# nrf7120E_enga_application register map
Vendor: Nordic Semiconductor; Series: nrf71; File version: 1
CPU: CM33 r0p4, little endian, MPU, FPU, 3 interrupt priority bits, 270 interrupts, 4 SAU regions
Registers are 32-bit, read-write, reset 0x0 unless marked. A register's access mark holds for its fields unless they carry their own. Offsets are from the block's base; [hi:lo] are bit positions; lines under a group give offsets from that group; {n}, {i} and the like mark numbered series; 'fields as' and 'values as' point back to an identical list.

## GLOBAL_MRAMC_S — MRAM controller
Base 0x5004E000
0x100 EVENTS_READY — Current operation is completed
  [0] EVENTS_READY
    0=NotGenerated (Event not generated); 1=Generated (Event generated)
0x104 EVENTS_READYNEXT — Ready to accept a new write operation
  [0] EVENTS_READYNEXT
    values as EVENTS_READY.EVENTS_READY
0x108 EVENTS_ECCERROR — ECC error detected but not corrected.
  [0] EVENTS_ECCERROR
    values as EVENTS_READY.EVENTS_READY
0x10C EVENTS_ECCERRORCORR — ECC error detected and corrected.
  [0] EVENTS_ECCERRORCORR
    values as EVENTS_READY.EVENTS_READY
0x110 EVENTS_TRIMCONFIGREQ — MRAM trim configuration request. The MRAMC is ready for the MRAM trim configuration.
  [0] EVENTS_TRIMCONFIGREQ
    values as EVENTS_READY.EVENTS_READY
0x114 EVENTS_ACCESSERR — MRAM access error.
  [0] EVENTS_ACCESSERR
    values as EVENTS_READY.EVENTS_READY
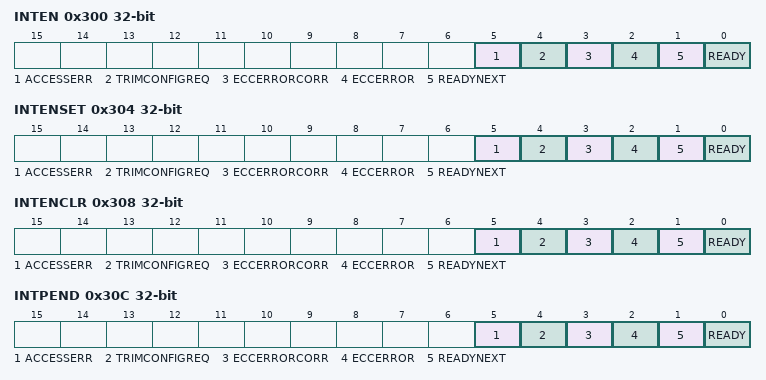
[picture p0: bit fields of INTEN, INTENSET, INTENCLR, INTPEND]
0x300 INTEN — Enable or disable interrupt
  [all] fields
    0=Disabled; 1=Enabled
  [5] ACCESSERR — Enable or disable interrupt for event ACCESSERR
  [4] TRIMCONFIGREQ — Enable or disable interrupt for event TRIMCONFIGREQ
  [3] ECCERRORCORR — Enable or disable interrupt for event ECCERRORCORR
  [2] ECCERROR — Enable or disable interrupt for event ECCERROR
  [1] READYNEXT — Enable or disable interrupt for event READYNEXT
  [0] READY — Enable or disable interrupt for event READY
0x304 INTENSET — Enable interrupt
  [all] fields
    on read: 0=Disabled (Read: Disabled); 1=Enabled (Read: Enabled) | on write: 1=Set (Enable)
  [5] ACCESSERR write-1-sets — Write '1' to enable interrupt for event ACCESSERR
  [4] TRIMCONFIGREQ write-1-sets — Write '1' to enable interrupt for event TRIMCONFIGREQ
  [3] ECCERRORCORR write-1-sets — Write '1' to enable interrupt for event ECCERRORCORR
  [2] ECCERROR write-1-sets — Write '1' to enable interrupt for event ECCERROR
  [1] READYNEXT write-1-sets — Write '1' to enable interrupt for event READYNEXT
  [0] READY write-1-sets — Write '1' to enable interrupt for event READY
0x308 INTENCLR — Disable interrupt
  [all] fields
    on read: 0=Disabled (Read: Disabled); 1=Enabled (Read: Enabled) | on write: 1=Clear (Disable)
  [5] ACCESSERR write-1-clears — Write '1' to disable interrupt for event ACCESSERR
  [4] TRIMCONFIGREQ write-1-clears — Write '1' to disable interrupt for event TRIMCONFIGREQ
  [3] ECCERRORCORR write-1-clears — Write '1' to disable interrupt for event ECCERRORCORR
  [2] ECCERROR write-1-clears — Write '1' to disable interrupt for event ECCERROR
  [1] READYNEXT write-1-clears — Write '1' to disable interrupt for event READYNEXT
  [0] READY write-1-clears — Write '1' to disable interrupt for event READY
0x30C INTPEND ro — Pending interrupts
  [all] fields
    on read: 0=NotPending (Read: Not pending); 1=Pending (Read: Pending)
  [5] ACCESSERR — Read pending status of interrupt for event ACCESSERR
  [4] TRIMCONFIGREQ — Read pending status of interrupt for event TRIMCONFIGREQ
  [3] ECCERRORCORR — Read pending status of interrupt for event ECCERRORCORR
  [2] ECCERROR — Read pending status of interrupt for event ECCERROR
  [1] READYNEXT — Read pending status of interrupt for event READYNEXT
  [0] READY — Read pending status of interrupt for event READY
0x400 READY ro — MRAMC current operation status.
  [0] READY — MRAMC is ready or busy
    0=Busy (MRAMC is busy); 1=Ready (Current operation is completed and MRAMC is ready)
0x404 READYNEXT ro — Ready next flag.
  [0] READYNEXT — MRAMC can accept a new write operation
    0=Busy (MRAMC cannot accept any write operation now); 1=Ready (MRAMC is ready to accept a new write operation)
0x410 ECC group — Unspecified
  0x00 ERROR — ECC Error status.
    [0] ECCERROR — ECC error detected for a read which could not be corrected. Write 0 to clear.
      0=NoEccError (ECC error not detected); 1=ECC error detected
  0x04 ERRORCORR — ECC error detected and corrected.
    [0] ERRORCORR — ECC error detected and corrected for a read. Write 0 to clear.
      0=NoEccError (ECC error not detected); 1=ErrorCorr (ECC error detected and corrected)
  0x08 ERRORADDR ro reset 0xFFFFFFFF — Address of the first ECC error that could not be corrected.
    [31:0] ERRORADDR — Address
  0x0C CORRADDR ro reset 0xFFFFFFFF — Address of the first ECC error that was corrected.
    [31:0] CORRADDR — Address
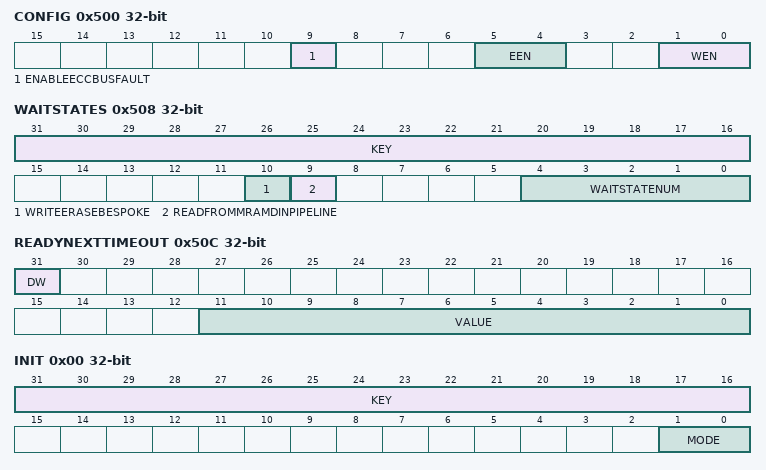
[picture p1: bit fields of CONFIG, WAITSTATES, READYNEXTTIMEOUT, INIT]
0x500 CONFIG — Configuration register
  [9] ENABLEECCBUSFAULT — Enable or disable bus fault on ECC failure during read.
    0=Enable bus fault on ECC failure during MRAM read; 1=Disable bus fault on ECC failure during MRAM read
  [5:4] EEN — Erase enable.
    0=DisableErase (Erase is disabled but read is allowed); 1=EnablePageErase (Erase page and read are allowed); 2=EnableWordErase (Erase word and read are allowed)
  [1:0] WEN — Write enable.
    0=DisableWrite (Write is disabled); 1=EnableNormalWrite (Normal write is enabled); 2=EnableDirectWrite (Direct write is enabled)
0x504 AUTOREADMODE — Automatically disables the write and erases on timeout and enters into read mode.
  [11:0] VALUE — Timeout value to disable write and erase.
0x508 WAITSTATES — Waitstates for MRAM read access
  [31:16] KEY — Key to enable the writing to this register.
    0=Disable the writing to this register; 0xA66D=Enable the writing to this register
  [10] WRITEERASEBESPOKE — Select the operational mode for the bespoke request.
    0=ModeEntryExit (Send the bespoke signal when entering either write or erase mode, and release the request when exiting those modes.); 1=ModeEnable (Send the bespoke request when a write or an erase is enabled in.)
  [9] READFROMMRAMDINPIPELINE — Register to enable or disable reading data pending to be committed to MRAM from the data input pipeline if the data at the requested read address is already present in the MRAM data input pipeline. Only applicable for direct write mode.
    0=Disable reading uncommitted data from MRAM data input pipeline; 1=Enable reading uncommitted data from MRAM data input pipeline
  [4:0] WAITSTATENUM — Register to read the current number of waitstate for the MRAM access and set a new value
0x50C READYNEXTTIMEOUT — Preload timeout value for waiting for a next write
  [31] DW — Triggers a write to MRAMC macro on the ready next timeout in direct write mode (CONFIG.WEN = 2) and some data written into the internal write buffer.
    0=Disable (No write trigger); 1=Enable (Write trigger)
  [11:0] VALUE — Preload value
0x510 LOWAVGCURR group — Unspecified
  0x00 READ — Preload timeout value for low average current in case of read
    [11:0] VALUE — Preload value
  0x04 WRITE — Preload timeout value for low average current in case of write
    [11:0] VALUE — Preload value
  0x08 ERASE — Preload timeout value for low average current in case of erase
    [11:0] VALUE — Preload value
0x520 POWER group — Unspecified
  0x00 INIT — Initiates power up or down sequence.
    [31:16] KEY — Key to enable the writing to this register.
      values as WAITSTATES.KEY
    [1:0] MODE — Power mode.
      0=NoOperation (No change in power mode); 1=PowerUp (Triggers power up sequence. Ignored if MRAM is already in Active mode or Standby mode.); 2=PowerDown (Initiates power down sequence. Ignored if MRAM is already in MRAM_OFF mode.); 3=PowerDownTrimRet (Initiates power down sequence with trim retained. Ignored if MRAM is already in MRAM_OFF_TRIM_RETAIN mode.)
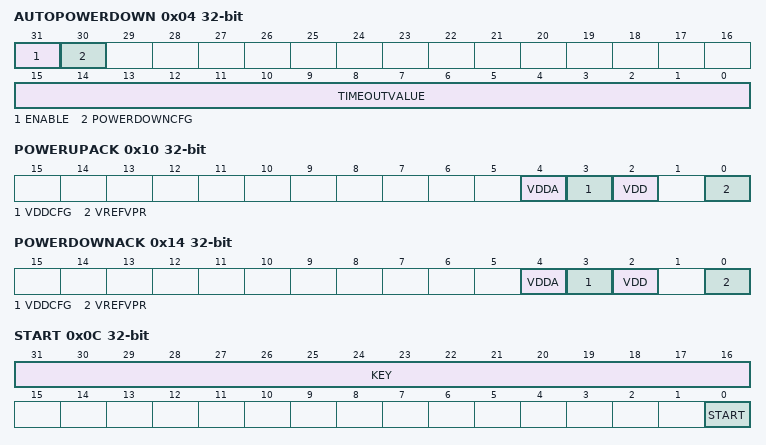
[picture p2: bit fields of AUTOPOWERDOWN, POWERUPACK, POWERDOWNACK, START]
  0x04 AUTOPOWERDOWN — Configures the automatic power down feature using the inactive time period of MRAM.
    [31] ENABLE — Enable the automatic power down feature.
      0=Disable the automatic power down feature; 1=Enable the automatic power down feature
    [30] POWERDOWNCFG — Power down mode when the timeout happens.
      0=MramOffTrimRetain (Power mode is MRAM_OFF_TRIM_RETAIN); 1=MramOff (Power mode is MRAM_OFF)
    [15:0] TIMEOUTVALUE — Timeout value for the power down.
  0x0C STATUS ro — Status of the power up/down sequence.
    [3:0] STATE — The current power up/down state.
      0=Off (MRAM is OFF); 1=PowerUpSeq (MRAM power up sequence is active); 2=TrimConfigSeq (Request for the MRAM trim configuration.); 3=TrimConfigWait (Waiting for the MRAM trim configuration to complete.); 4=TrimConfigDone (The MRAM trim configuration to completed (This is momentary state).); 5=Standby (MRAM is in standby mode.); 6=Active (MRAM is in active mode (or in standby mode)); 7=PowerDownSeq (MRAM power down sequence is active); 8=OffTrimRetain (MRAM is OFF with trim configuration in retain)
  0x10 POWERUPACK ro — Status of the power control signals acknowledgement during power up sequence.
    [all] fields
      0=Busy; 1=Ready
    [4] VDDA — Waiting for VDDA up ACK or not
    [3] VDDCFG — Waiting for VDD_CFG up ACK or not
    [2] VDD — Waiting for VDD up ACK or not
    [0] VREFVPR — Waiting for VREF and VPR up ACK or not
  0x14 POWERDOWNACK ro — Status of the power control signals acknowledgement during power down sequence.
    [all] fields
      0=Busy; 1=Ready
    [4] VDDA — Waiting for VDDA down ACK or not
    [3] VDDCFG — Waiting for VDD_CFG down ACK or not
    [2] VDD — Waiting for VDD down ACK or not
    [0] VREFVPR — Waiting for VREF and VPR down ACK or not
0x540 TRIM group — Unspecified
  0x00 DATAIN reset 0xFFFFFFFF — Data to be written to the MRAM trim configuration.
    [31:0] DATAIN — Data
  0x04 DATAOUT ro — Data read from the MRAM trim configuration.
    [31:0] DATAOUT — Data
  0x08 COUNT reset 0x20 — Number of bits in the current data to be written to and read from the trim configuration.
    [5:0] COUNT — Number of bits to be written.
  0x0C START — Start shifting data for trim configuration.
    [31:16] KEY — Key to enable the writing to this register.
      values as WAITSTATES.KEY
    [0] START — Start trim configuration
      0=NoOperation; 1=Start trim config
  0x10 READY ro reset 0x1 — Status of shifting the MRAM trim configuration data.
    [0] READY — Shifting the MRAM trim configuration data is in progress or not.
      0=Busy (Shifting the MRAM trim configuration data is in progress.); 1=Ready for shifting the next MRAM trim configuration data
  0x14 DONE — This register is used to indicate to the MRAMC that the whole MRAM trim configuration data write is completed.
    [31:0] TRIMCOMPLETED — Trim configuration is completed.
      on read: 0=TrimUnknown (Read: Trim configuration is unknown); 1=TrimCompleted (Read: Trim configuration data write is completed.) | on write: 0xA66DA66D=TrimComplete (Write: Trim configuration data write is complete.); 0=NoOperation (Write ignored for all other values than 0xA66DA66D.)
0x560 ERASE group — Unspecified
  0x00 ERASEWORD — Register for erasing a word in the MRAM main block.
    [31:0] ERASEWORD — Address of the word that needs to be erased.
  0x04 SIZE — Size for erasing an area in the MRAM main block
    [18:0] SIZE — Number of MRAM words to be erased using ERASE.ERASEAREA.
  0x08 ERASEAREA — Register for erasing an area in the MRAM main block
    [31:0] ERASEAREA — Start address of the area to be erased.
  0x0C ERASEALL wo — Register for erasing whole MRAM main block and the first NVR page This register is deprecated and must not be used. Use ERASEALL from CTRLAP instead.
    [0] ERASEALL — Erase whole MRAM and the first NVR page. The other NVR pages are not erased.
      0=NoOperation; 1=Erase (Start erase of chip)
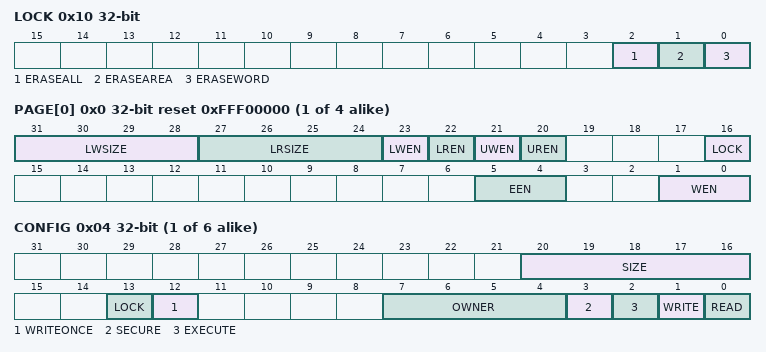
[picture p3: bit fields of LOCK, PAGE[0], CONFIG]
  0x10 LOCK — Locking the erase registers.
    [all] fields
      0=Disabled (Lock disabled.); 1=Enabled (Lock enabled.)
    [2] ERASEALL — Lock for ERASE.ERASEALL.
    [1] ERASEAREA — Lock for ERASE.ERASEAREA.
    [0] ERASEWORD — Lock for ERASE.ERASEWORD.
0x580 CONFIGNVR group — Unspecified
  {0x0+4j} PAGE[{j}] (j=0..3) reset 0xFFF00000 — Description collection: Configuration register for NVR page n
    [31:28] LWSIZE — Size of part of the lower 2KB memory in the NVR page to disable write access
    [27:24] LRSIZE — Size of part of the lower 2KB memory in the NVR page to disable read access
    [23] LWEN write-0-clears — Enable write access to the lower range of the NVR page, as defined by LWSIZE
      0=Disabled (Write is disabled.); 1=Enabled (Write is enabled)
    [22] LREN write-0-clears — Enable read access to the lower range of the NVR page, as defined by LRSIZE
      0=Disabled (Read is disabled.); 1=Enabled (Read is enabled)
    [21] UWEN write-0-clears — Enable write access to the upper part of NVR page, where the upper part size is NVR page size - 2KB
      values as LWEN
    [20] UREN write-0-clears — Enable read access to the upper part of NVR page, where the upper part size is NVR page size - 2KB
      0=Disabled (Read is disabled.); 1=Enabled (Read is enabled)
    [16] LOCK write-1-sets — Enables the lock for this register.
      0=LockDisabled (Lock is disabled); 1=LockEnabled (Lock is enabled)
    [5:4] EEN — Erase enable.
      values as CONFIG.EEN
    [1:0] WEN — Write enable.
      values as CONFIG.WEN
{0x5A0+8i} REGION[{i}] (i=0..5) group — Unspecified
  0x00 ADDRESS — Description cluster: Region address
    [31:0] STARTADDR — Start address of the region [n]
  0x04 CONFIG — Description cluster: Region configuration
    [20:16] SIZE — Size in KBytes of region [n]
    [13] LOCK write-1-sets — Enable lock
      0=Disabled (Lock disabled for region [n]); 1=Enabled (Lock enabled for region [n])
    [12] WRITEONCE
      0=Disabled (Write-once disabled); 1=Enabled (Write-once enabled)
    [7:4] OWNER — Owner ID
      0=NotEnforced (Owner ID protection is not enforced)
    [3] SECURE — Secure access
      0=NonSecure (Both Secure and non-Secure access to override region [n] is allowed); 1=Secure (Only secure access to override region [n] is allowed)
    [2] EXECUTE — Execute access
      0=NotAllowed (Execute access to override region [n] is not allowed); 1=Allowed (Execute access to override region [n] is allowed)
    [1] WRITE — Write access
      0=NotAllowed (Write access to override region [n] is not allowed); 1=Allowed (Write access to override region [n] is allowed)
    [0] READ — Read access
      0=NotAllowed (Read access to override region [n] is not allowed); 1=Allowed (Read access to override region [n] is allowed)
